# NSUC1602 register map
Vendor: ARM Ltd.; Series: NSUC1602; File version: 0.0
CPU: CM3 r1p0, little endian, MPU, no FPU, 3 interrupt priority bits
Registers are 32-bit, read-write, reset 0x0 unless marked. A register's access mark holds for its fields unless they carry their own. Offsets are from the block's base; [hi:lo] are bit positions; {n}, {i} and the like mark numbered series.

## EPWM — S/T bus
Base 0x40021000
0x00 PWMENABLE — PWM输出使能寄存器
  [0] PWMOE
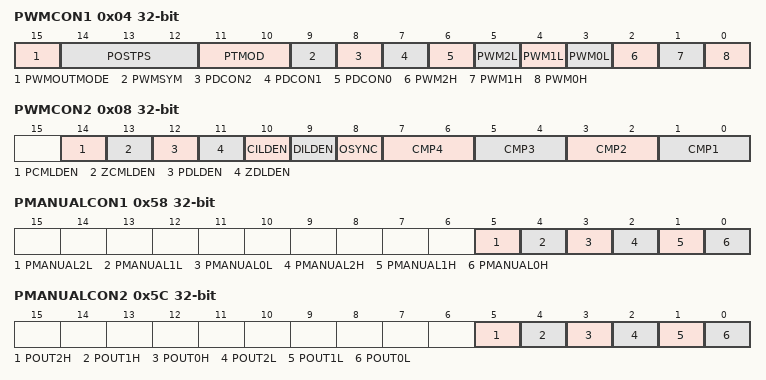
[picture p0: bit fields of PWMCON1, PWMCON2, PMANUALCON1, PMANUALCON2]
0x04 PWMCON1 (reset mask 0x1337F7F) — PWM模块控制寄存器1
  [15] PWMOUTMODE, [14:12] POSTPS, [11:10] PTMOD, [9] PWMSYM, [8] PDCON2, [7] PDCON1, [6] PDCON0, [5] PWM2L, [4] PWM1L, [3] PWM0L, [2] PWM2H, [1] PWM1H, [0] PWM0H
0x08 PWMCON2 (reset mask 0x1337F7F) — PWM模块控制寄存器2
  [14] PCMLDEN, [13] ZCMLDEN, [12] PDLDEN, [11] ZDLDEN, [10] CILDEN, [9] DILDEN, [8] OSYNC, [2n-1:2n-2] CMP{n} (n=1..4)
0x0C PWMPERIOD (reset mask 0x1337F7F) — PWM周期寄存器
  [15:0] PWMP
0x14 PWMPSQ (reset mask 0x1337F7F) — PWM时钟预分频寄存器
  [15:0] PWMPSQ
0x18 PWM0DH (reset mask 0x1337F7F) — PWM0H占空比寄存器1
  [15:0] PWM0DH
{0x1C+8i} PWM{i}DL (reset mask 0x1337F7F) (i=0..2) — PWM{i}L占空比寄存器2
  [15:0] PWM{i}DL
0x20 PWM1DH (reset mask 0x1337F7F) — PWM1H占空比寄存器1
  [15:0] PWM1DH
0x28 PWM2DH (reset mask 0x1337F7F) — PWM2H占空比寄存器2
  [15:0] PWM2DH
{0x2C+4i} PWMCMP{i} (reset mask 0x1337F7F) (i=1..4) — 事件触发比较寄存器{i}
  [15:0] PWMCMP{i}
{0x40+8i} PWMDT{i}H (reset mask 0x1337F7F) (i=0..2) — PWM通道{i}H上升沿死区控制寄存器
  [15:0] PWMDT{i}H
{0x44+8i} PWMDT{i}L (reset mask 0x1337F7F) (i=0..2) — PWM通道{i}L上升沿死区控制寄存器
  [15:0] PWMDT{i}L
0x58 PMANUALCON1 — PWM0/1/2手动输出设置寄存器1
  [5] PMANUAL2L, [4] PMANUAL1L, [3] PMANUAL0L, [2] PMANUAL2H, [1] PMANUAL1H, [0] PMANUAL0H
0x5C PMANUALCON2 — PWM0/1/2手动输出设置寄存器2
  [5] POUT2H, [4] POUT1H, [3] POUT0H, [2] POUT2L, [1] POUT1L, [0] POUT0L
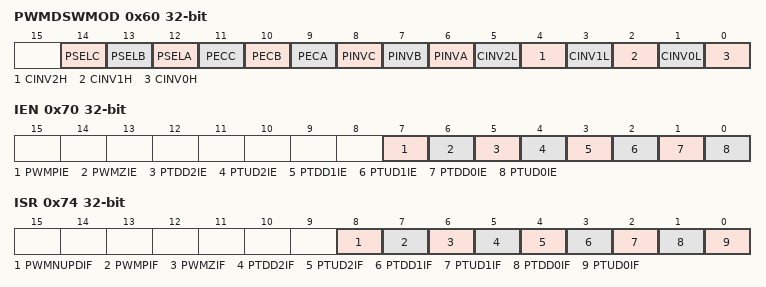
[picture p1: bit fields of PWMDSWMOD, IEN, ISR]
0x60 PWMDSWMOD (reset mask 0x1337F7F) — PWM Double Switch 模式
  [14] PSELC, [13] PSELB, [12] PSELA, [11] PECC, [10] PECB, [9] PECA, [8] PINVC, [7] PINVB, [6] PINVA, [5] CINV2L, [4] CINV2H, [3] CINV1L, [2] CINV1H, [1] CINV0L, [0] CINV0H
0x70 IEN (reset mask 0x1337F7F) — PWM中断使能控制寄存器
  [7] PWMPIE, [6] PWMZIE, [5] PTDD2IE, [4] PTUD2IE, [3] PTDD1IE, [2] PTUD1IE, [1] PTDD0IE, [0] PTUD0IE
0x74 ISR (reset mask 0x1337F7F) — PWM中断标志和清除寄存器
  [8] PWMNUPDIF, [7] PWMPIF, [6] PWMZIF, [5] PTDD2IF, [4] PTUD2IF, [3] PTDD1IF, [2] PTUD1IF, [1] PTDD0IF, [0] PTUD0IF
0x78 PWMRWEN (reset mask 0x1337F7F) — 寄存器修改和重载控制寄存器
  [7:0] PWMRLDEN

## ADC — S/T bus
Base 0x40022000
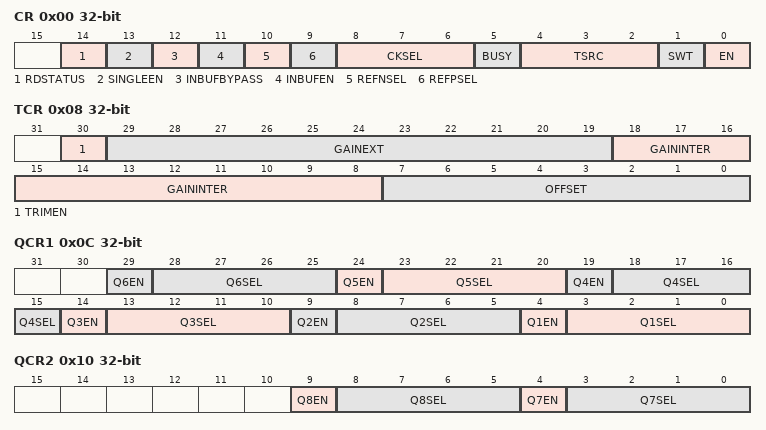
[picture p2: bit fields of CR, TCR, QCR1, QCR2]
0x00 CR (reset mask 0x1337F7F) — ADC控制寄存器
  [14] RDSTATUS ro, [13] SINGLEEN, [12] INBUFBYPASS, [11] INBUFEN, [10] REFNSEL, [9] REFPSEL, [8:6] CKSEL, [5] BUSY ro, [4:2] TSRC, [1] SWT, [0] EN
0x04 SCR — ADC采样控制寄存器
  [5:0] SAMP
0x08 TCR (reset mask 0x1337F7F) — ADC校准配置寄存器
  [30] TRIMEN, [29:19] GAINEXT, [18:8] GAININTER, [7:0] OFFSET
0x0C QCR1 (reset mask 0x1337F7F) — ADC队列控制寄存器1
  [5n-1] Q{n}EN (n=1..6), [5n-2:5n-5] Q{n}SEL (n=1..6)
0x10 QCR2 (reset mask 0x1337F7F) — ADC队列控制寄存器2
  [9] Q8EN, [8:5] Q8SEL, [4] Q7EN, [3:0] Q7SEL
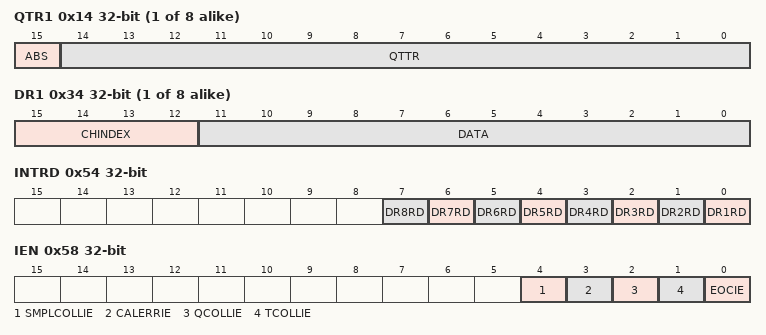
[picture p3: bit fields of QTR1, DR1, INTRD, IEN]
{0x10+4i} QTR{i} (reset mask 0x1337F7F) (i=1..8) — 队列启动切换时间
  [15] ABS, [14:0] QTTR
{0x30+4i} DR{i} (reset mask 0x1337F7F) (i=1..8) — ADC 数据寄存器
  [15:12] CHINDEX ro, [11:0] DATA ro
0x54 INTRD (reset mask 0x1337F7F) — 已读标志位寄存器
  [n-1] DR{n}RD ro (n=1..8)
0x58 IEN — 中断使能寄存器
  [4] SMPLCOLLIE, [3] CALERRIE, [2] QCOLLIE, [1] TCOLLIE, [0] EOCIE
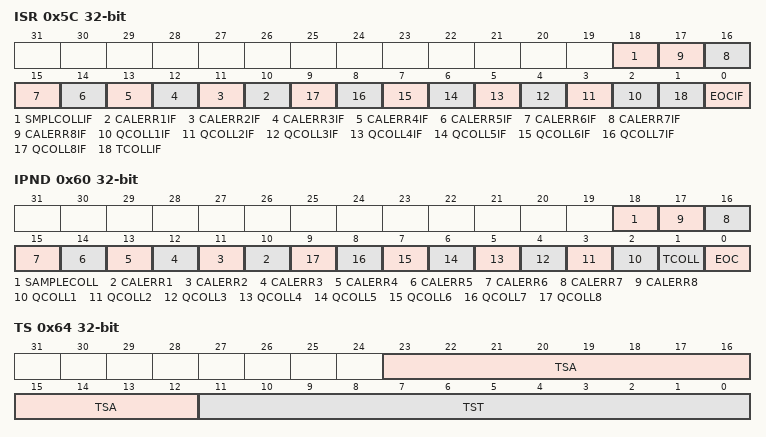
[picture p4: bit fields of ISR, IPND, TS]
0x5C ISR (reset mask 0x1337F7F) — 中断置起状态寄存器
  [18] SMPLCOLLIF, [n+9] CALERR{n}IF (n=1..8), [n+1] QCOLL{n}IF (n=1..8), [1] TCOLLIF, [0] EOCIF
0x60 IPND (reset mask 0x1337F7F) — 中断使能置起状态寄存器
  [18] SAMPLECOLL, [n+9] CALERR{n} (n=1..8), [n+1] QCOLL{n} (n=1..8), [1] TCOLL, [0] EOC
0x64 TS (reset mask 0x1337F7F) — 温度传感器校准寄存器
  [23:12] TSA, [11:0] TST

## GPIO — S/T bus
Base 0x40025000
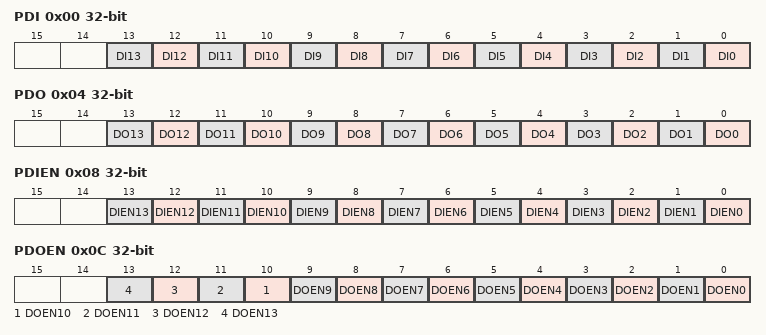
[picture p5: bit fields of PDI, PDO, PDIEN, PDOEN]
0x00 PDI (reset mask 0x1337F7F) — GPIO 端口输入数据寄存器
  [n] DI{n} ro (n=0..13)
0x04 PDO (reset mask 0x1337F7F) — GPIO 输出数据寄存器
  [n] DO{n} (n=0..13)
0x08 PDIEN (reset mask 0x1337F7F) — GPIO 输入使能寄存器
  [n] DIEN{n} (n=0..13)
0x0C PDOEN (reset mask 0x1337F7F) — GPIO 输出使能寄存器
  [n] DOEN{n} (n=0..13)
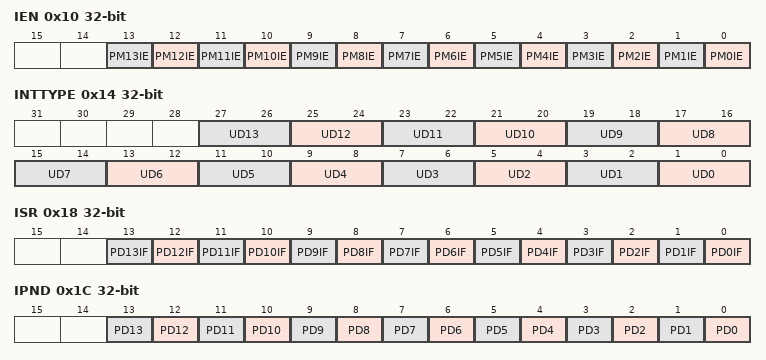
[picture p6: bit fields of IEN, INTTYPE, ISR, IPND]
0x10 IEN (reset mask 0x1337F7F) — GPIO 中断使能寄存器
  [n] PM{n}IE (n=0..13)
0x14 INTTYPE (reset mask 0x1337F7F) — GPIO触发模式寄存器
  [2n+1:2n] UD{n} (n=0..13)
0x18 ISR (reset mask 0x1337F7F) — GPIO中断状态寄存器
  [n] PD{n}IF (n=0..13)
0x1C IPND (reset mask 0x1337F7F) — GPIO中断状态使能寄存器
  [n] PD{n} (n=0..13)
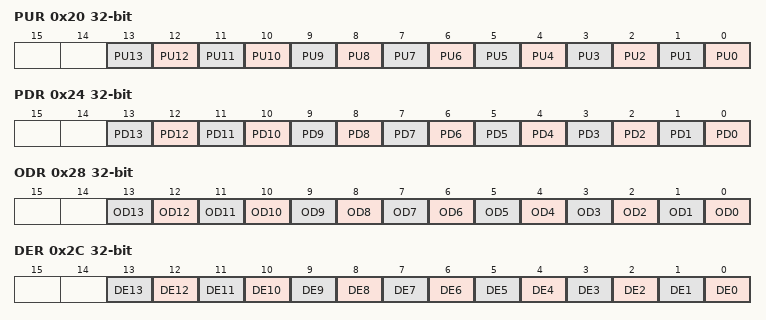
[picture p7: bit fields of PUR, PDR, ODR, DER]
0x20 PUR (reset mask 0x1337F7F) — GPIO上拉使能寄存器
  [n] PU{n} (n=0..13)
0x24 PDR (reset mask 0x1337F7F) — GPIO下拉使能寄存器
  [n] PD{n} (n=0..13)
0x28 ODR (reset mask 0x1337F7F) — GPIO输出类型寄存器
  [n] OD{n} (n=0..13)
0x2C DER (reset mask 0x1337F7F) — GPIO同步使能寄存器
  [n] DE{n} (n=0..13)
0x30 DTR — GPIO消抖设置寄存器
  [2:0] DT
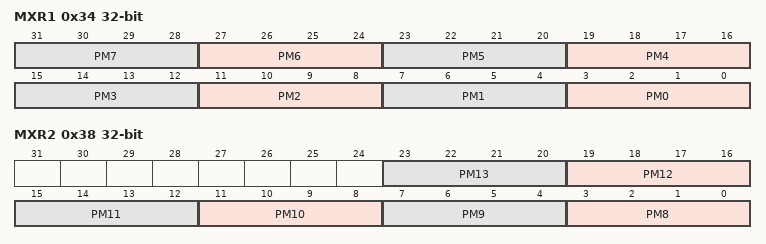
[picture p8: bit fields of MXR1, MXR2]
0x34 MXR1 (reset mask 0x1337F7F) — GPIO功能复用寄存器1
  [4n+3:4n] PM{n} (n=0..7)
0x38 MXR2 (reset mask 0x1337F7F) — GPIO功能复用寄存器2
  [4n-29:4n-32] PM{n} (n=8..13)
